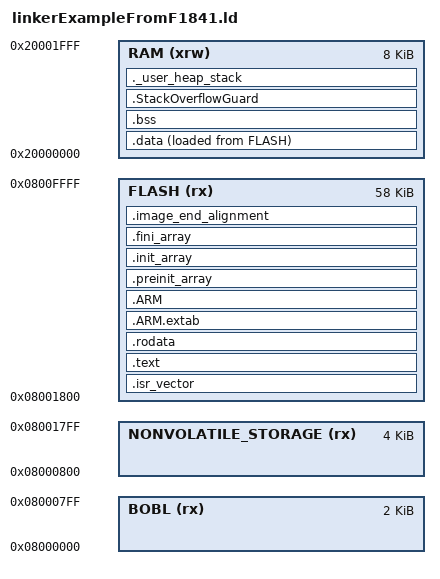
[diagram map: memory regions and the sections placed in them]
/*
******************************************************************************
**

**  File        : LinkerScript.ld
**
**  Author		: Auto-generated by System Workbench for STM32
**
**  Abstract    : Linker script for STM32G071RBTx series
**                128Kbytes FLASH and 36Kbytes RAM
**
**                Set heap size, stack size and stack location according
**                to application requirements.
**
**                Set memory bank area and size if external memory is used.
**
**  Target      : STMicroelectronics STM32
**
**  Distribution: The file is distributed “as is,” without any warranty
**                of any kind.
**
*****************************************************************************
** @attention
**
** <h2><center>&copy; COPYRIGHT(c) 2019 STMicroelectronics</center></h2>
**
** Redistribution and use in source and binary forms, with or without modification,
** are permitted provided that the following conditions are met:
**   1. Redistributions of source code must retain the above copyright notice,
**      this list of conditions and the following disclaimer.
**   2. Redistributions in binary form must reproduce the above copyright notice,
**      this list of conditions and the following disclaimer in the documentation
**      and/or other materials provided with the distribution.
**   3. Neither the name of STMicroelectronics nor the names of its contributors
**      may be used to endorse or promote products derived from this software
**      without specific prior written permission.
**
** THIS SOFTWARE IS PROVIDED BY THE COPYRIGHT HOLDERS AND CONTRIBUTORS "AS IS"
** AND ANY EXPRESS OR IMPLIED WARRANTIES, INCLUDING, BUT NOT LIMITED TO, THE
** IMPLIED WARRANTIES OF MERCHANTABILITY AND FITNESS FOR A PARTICULAR PURPOSE ARE
** DISCLAIMED. IN NO EVENT SHALL THE COPYRIGHT HOLDER OR CONTRIBUTORS BE LIABLE
** FOR ANY DIRECT, INDIRECT, INCIDENTAL, SPECIAL, EXEMPLARY, OR CONSEQUENTIAL
** DAMAGES (INCLUDING, BUT NOT LIMITED TO, PROCUREMENT OF SUBSTITUTE GOODS OR
** SERVICES; LOSS OF USE, DATA, OR PROFITS; OR BUSINESS INTERRUPTION) HOWEVER
** CAUSED AND ON ANY THEORY OF LIABILITY, WHETHER IN CONTRACT, STRICT LIABILITY,
** OR TORT (INCLUDING NEGLIGENCE OR OTHERWISE) ARISING IN ANY WAY OUT OF THE USE
** OF THIS SOFTWARE, EVEN IF ADVISED OF THE POSSIBILITY OF SUCH DAMAGE.
**
*****************************************************************************
*/

/* Entry Point */
ENTRY(Reset_Handler)

/* Generate a link error if heap and stack don't fit into RAM */
_Min_Heap_Size = 0x000;  /* required amount of heap  */
_Min_Stack_Size = 0x300; /* required amount of stack */

/* Specify the memory areas */
MEMORY
{
    RAM (xrw)                : ORIGIN = 0x20000000, LENGTH = 8K
    BOBL (rx)                : ORIGIN = 0x08000000, LENGTH = 0x00000800 /* Each eraseable sector is 2k. */
    NONVOLATILE_STORAGE (rx) : ORIGIN = 0x08000800, LENGTH = 0x00001000  /* Need 2 eraseable sectors. */
    FLASH (rx)               : ORIGIN = 0x08001800, LENGTH = 64k - 0x00001800
}

/* Highest address of the user mode stack */
_estack = ORIGIN(RAM) + LENGTH(RAM);    /* end of RAM */

VECT_TAB_OFFSET = ORIGIN(FLASH);

_BOOT_ONLY_BOOTLOADER_MEMORY_START    = ORIGIN(BOBL);
_BOOT_ONLY_BOOTLOADER_MEMORY_END      = ORIGIN(BOBL) + LENGTH(BOBL) - 1;

/* You can use these in the C environment by externing as a variable
 * and casting as the desired type.  It's really weird...don't think
 * about it too hard; just do this:
 *
 *     extern uint8_t _NONVOLATILE_STORAGE_START;
 *
 *     uint8_t* get_general_nonvolatile_storage_start_address(void)
 *     {
 *         return &_NONVOLATILE_STORAGE_START;
 *     }
 */
_BOOT_ONLY_BOOTLOADER_MEMORY_START    = ORIGIN(BOBL);
_BOOT_ONLY_BOOTLOADER_MEMORY_END      = ORIGIN(BOBL) + LENGTH(BOBL) - 1;
_BOOTLOADER_MEMORY_START              = _BOOT_ONLY_BOOTLOADER_MEMORY_START;
_BOOTLOADER_MEMORY_END                = _BOOT_ONLY_BOOTLOADER_MEMORY_END;
_LOWEST_USED_FLASH_ADDRESS            = ORIGIN(FLASH);
_NONVOLATILE_STORAGE_START            = ORIGIN(NONVOLATILE_STORAGE);
_NONVOLATILE_STORAGE_END              = ORIGIN(NONVOLATILE_STORAGE) + LENGTH(NONVOLATILE_STORAGE) - 1;
_NONVOLATILE_STORAGE_1ST_GROUP_START  = _NONVOLATILE_STORAGE_START;
_NONVOLATILE_STORAGE_2ND_GROUP_START  = ORIGIN(NONVOLATILE_STORAGE) + (LENGTH(NONVOLATILE_STORAGE) / 2);

/* Define output sections */
SECTIONS
{
  /* The startup code goes first into FLASH */
  .isr_vector :
  {
    . = ALIGN(8);
    KEEP(*(.isr_vector)) /* Startup code */
    . = ALIGN(8);
  } >FLASH

  /* The program code and other data goes into FLASH */
  .text :
  {
    . = ALIGN(8);

    /* On most other projects the mule application's bootloader metadata is 
     * placed BEFORE the final application's isr vector (i.e. outside of the 
     * final application's image space), but in this project we want to 
     * preserve it (and thus need it INSIDE the final application's image 
     * space) so that one box has all the information necessary to send to the 
     * next box, because we want to be able to have boxes independently update 
     * other boxes in the system, by "cloning" themselves.
     */
    FILL(0xFFFFFFFF) /* fill these 72 bytes with 0xFF, otherwise the default is 0x00, which is fine I guess, but meh let's just not write to it */
    . += 72; /* reserve room for mule application's bootloader metadata */

    KEEP(*(.bootloader_metadata))  /* Ensures the metadata isn't optimized */
    *(.text)           /* .text sections (code) */
    *(.text*)          /* .text* sections (code) */
    *(.glue_7)         /* glue arm to thumb code */
    *(.glue_7t)        /* glue thumb to arm code */
    *(.eh_frame)

    KEEP (*(.init))
    KEEP (*(.fini))

    . = ALIGN(4);
    _etext = .;        /* define a global symbols at end of code */
  } >FLASH

  /* Constant data goes into FLASH */
  .rodata :
  {
    . = ALIGN(4);
    *(.rodata)         /* .rodata sections (constants, strings, etc.) */
    *(.rodata*)        /* .rodata* sections (constants, strings, etc.) */
    . = ALIGN(4);
  } >FLASH

  .ARM.extab   : { *(.ARM.extab* .gnu.linkonce.armextab.*) } >FLASH
  .ARM : {
    __exidx_start = .;
    *(.ARM.exidx*)
    __exidx_end = .;
  } >FLASH

  .preinit_array     :
  {
    PROVIDE_HIDDEN (__preinit_array_start = .);
    KEEP (*(.preinit_array*))
    PROVIDE_HIDDEN (__preinit_array_end = .);
  } >FLASH
  .init_array :
  {
    PROVIDE_HIDDEN (__init_array_start = .);
    KEEP (*(SORT(.init_array.*)))
    KEEP (*(.init_array*))
    PROVIDE_HIDDEN (__init_array_end = .);
  } >FLASH
  .fini_array :
  {
    PROVIDE_HIDDEN (__fini_array_start = .);
    KEEP (*(SORT(.fini_array.*)))
    KEEP (*(.fini_array*))
    PROVIDE_HIDDEN (__fini_array_end = .);
  } >FLASH

  __etext = .;    /* define a global symbol at end of code */

  /* used by the startup to initialize data */
  _sidata = LOADADDR(.data);

  /* Initialized data sections goes into RAM, load LMA copy after code */
  .data : 
  {
    . = ALIGN(4);
    _sdata = .;        /* create a global symbol at data start */
    *(.data)           /* .data sections */
    *(.data*)          /* .data* sections */

    . = ALIGN(8);
    _edata = .;        /* define a global symbol at data end */
  } >RAM AT> FLASH

/* Make sure the last thing in the srec file is on an 8-byte boundary, so when 
 * the image is shifted to be in front of the mule application and we append 
 * the mule application's bootloader metadata to the beginning, the mule 
 * application's bootloader metadata is also on an 8-byte boundary.
 */
.image_end_alignment :
  {
    . = ALIGN(8);
    BYTE(0x77)
    BYTE(0x88)
    BYTE(0x99)
    BYTE(0xAA)
    BYTE(0xBB)
    BYTE(0xCC)
    BYTE(0xDD)
    BYTE(0xEE)
  } >FLASH
  
  /* Uninitialized data section */
  . = ALIGN(4);
  .bss :
  {
    /* This is used by the startup in order to initialize the .bss secion */
    _sbss = .;         /* define a global symbol at bss start */
    __bss_start__ = _sbss;
    *(.bss)
    *(.bss*)
    *(COMMON)

    . = ALIGN(4);
    _ebss = .;         /* define a global symbol at bss end */
    __bss_end__ = _ebss;
  } >RAM

  /* Allocates a region which the application can
   * fill with a pattern, and periodically check the pattern to determine if
   * anything has erroneously written to that region.
   */
  .StackOverflowGuard :
  {
    _STACK_OVERFLOW_GUARD_START = .;
    KEEP(*(.stack_overflow_guard))
    . += 64; /* I normally keep this at 256 for development, but can reduce it for production */
    _STACK_OVERFLOW_GUARD_END = .;
  } > RAM

  /* User_heap_stack section, used to check that there is enough RAM left */
  ._user_heap_stack :
  {
    . = ALIGN(8);
    PROVIDE ( end = . );
    PROVIDE ( _end = . );
    . = . + _Min_Heap_Size;
    . = . + _Min_Stack_Size;
    . = ALIGN(8);
  } >RAM

  

  /* Remove information from the standard libraries */
  /DISCARD/ :
  {
    libc.a ( * )
    libm.a ( * )
    libgcc.a ( * )
  }

  .ARM.attributes 0 : { *(.ARM.attributes) }
}


